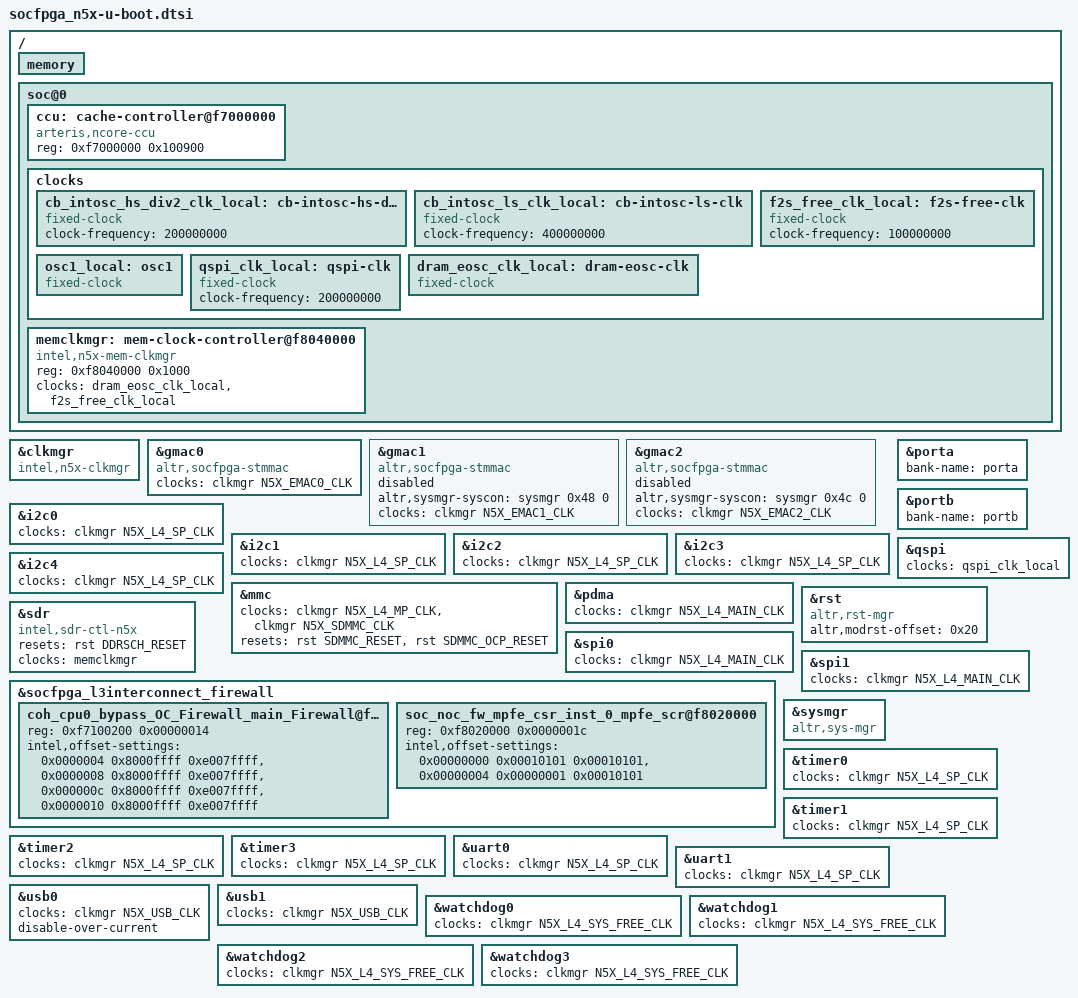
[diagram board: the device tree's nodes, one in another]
// SPDX-License-Identifier: GPL-2.0+
/*
 * U-Boot additions
 *
 * Copyright (C) 2020-2021 Intel Corporation <www.intel.com>
 */

#include "socfpga_soc64_u-boot.dtsi"
#include "socfpga_soc64_fit-u-boot.dtsi"
#include <dt-bindings/clock/n5x-clock.h>

/{
	memory {
		#address-cells = <2>;
		#size-cells = <2>;
		bootph-all;
	};

	soc@0 {
		bootph-all;

		ccu: cache-controller@f7000000 {
			compatible = "arteris,ncore-ccu";
			reg = <0xf7000000 0x100900>;
			bootph-all;
		};

		clocks {
			/* Local clock for U-Boot to see top-level clocks */
			cb_intosc_hs_div2_clk_local: cb-intosc-hs-div2-clk {
				#clock-cells = <0>;
				compatible = "fixed-clock";
				clock-frequency = <200000000>;
			};

			cb_intosc_ls_clk_local: cb-intosc-ls-clk {
				#clock-cells = <0>;
				compatible = "fixed-clock";
				clock-frequency = <400000000>;
			};

			f2s_free_clk_local: f2s-free-clk {
				#clock-cells = <0>;
				compatible = "fixed-clock";
				clock-frequency = <100000000>;
			};

			osc1_local: osc1 {
				#clock-cells = <0>;
				compatible = "fixed-clock";
			};

			qspi_clk_local: qspi-clk {
				#clock-cells = <0>;
				compatible = "fixed-clock";
				clock-frequency = <200000000>;
			};

			dram_eosc_clk_local: dram-eosc-clk {
				#clock-cells = <0>;
				compatible = "fixed-clock";
			};
		};

		memclkmgr: mem-clock-controller@f8040000 {
			compatible = "intel,n5x-mem-clkmgr";
			reg = <0xf8040000 0x1000>;
			#clock-cells = <0>;
			clocks = <&dram_eosc_clk_local>, <&f2s_free_clk_local>;
		};
	};
};

&clkmgr {
	compatible = "intel,n5x-clkmgr";
	bootph-all;
};

&gmac0 {
	compatible = "altr,socfpga-stmmac", "snps,dwmac-3.74a", "snps,dwmac";
	reset-names = "stmmaceth", "stmmaceth-ocp";
	clocks = <&clkmgr N5X_EMAC0_CLK>;
	clock-names = "stmmaceth";
	status = "okay";
};

&gmac1 {
	compatible = "altr,socfpga-stmmac", "snps,dwmac-3.74a", "snps,dwmac";
	reset-names = "stmmaceth", "stmmaceth-ocp";
	altr,sysmgr-syscon = <&sysmgr 0x48 0>;
	clocks = <&clkmgr N5X_EMAC1_CLK>;
	clock-names = "stmmaceth";
	status = "disabled";
};

&gmac2 {
	compatible = "altr,socfpga-stmmac", "snps,dwmac-3.74a", "snps,dwmac";
	reset-names = "stmmaceth", "stmmaceth-ocp";
	altr,sysmgr-syscon = <&sysmgr 0x4c 0>;
	clocks = <&clkmgr N5X_EMAC2_CLK>;
	clock-names = "stmmaceth";
	status = "disabled";
};

&i2c0 {
	clocks = <&clkmgr N5X_L4_SP_CLK>;
	reset-names = "i2c";
};

&i2c1 {
	clocks = <&clkmgr N5X_L4_SP_CLK>;
	reset-names = "i2c";
};

&i2c2 {
	clocks = <&clkmgr N5X_L4_SP_CLK>;
	reset-names = "i2c";
};

&i2c3 {
	clocks = <&clkmgr N5X_L4_SP_CLK>;
	reset-names = "i2c";
};

&i2c4 {
	clocks = <&clkmgr N5X_L4_SP_CLK>;
	reset-names = "i2c";
};

&memclkmgr {
	bootph-all;
};

&mmc {
	clocks = <&clkmgr N5X_L4_MP_CLK>,
		 <&clkmgr N5X_SDMMC_CLK>;
	resets = <&rst SDMMC_RESET>, <&rst SDMMC_OCP_RESET>;
};

&pdma {
	clocks = <&clkmgr N5X_L4_MAIN_CLK>;
};

&porta {
	bank-name = "porta";
};

&portb {
	bank-name = "portb";
};

&qspi {
	clocks = <&qspi_clk_local>;
	bootph-all;
};

&rst {
	compatible = "altr,rst-mgr";
	altr,modrst-offset = <0x20>;
	bootph-all;
};

&sdr {
	compatible = "intel,sdr-ctl-n5x";
	resets = <&rst DDRSCH_RESET>;
	clocks = <&memclkmgr>;
	clock-names = "mem_clk";
	bootph-all;
};

&spi0 {
	clocks = <&clkmgr N5X_L4_MAIN_CLK>;
};

&spi1 {
	clocks = <&clkmgr N5X_L4_MAIN_CLK>;
};

&socfpga_l3interconnect_firewall {
	coh_cpu0_bypass_OC_Firewall_main_Firewall@f7100200 {
		reg = <0xf7100200 0x00000014>;
		intel,offset-settings =
			/* Disable ocram security at CCU for non secure access */
			<0x0000004 0x8000ffff 0xe007ffff>,
			<0x0000008 0x8000ffff 0xe007ffff>,
			<0x000000c 0x8000ffff 0xe007ffff>,
			<0x0000010 0x8000ffff 0xe007ffff>;
		bootph-all;
	};

	soc_noc_fw_mpfe_csr_inst_0_mpfe_scr@f8020000 {
		reg = <0xf8020000 0x0000001c>;
		intel,offset-settings =
			/* Disable MPFE firewall for SMMU */
			<0x00000000 0x00010101 0x00010101>,
			/* Disable MPFE firewall for HMC adapter */
			<0x00000004 0x00000001 0x00010101>;
		bootph-all;
	};
};

&sysmgr {
	compatible = "altr,sys-mgr", "syscon";
	bootph-all;
};

&timer0 {
	clocks = <&clkmgr N5X_L4_SP_CLK>;
};

&timer1 {
	clocks = <&clkmgr N5X_L4_SP_CLK>;
};

&timer2 {
	clocks = <&clkmgr N5X_L4_SP_CLK>;
};

&timer3 {
	clocks = <&clkmgr N5X_L4_SP_CLK>;
};

&uart0 {
	clocks = <&clkmgr N5X_L4_SP_CLK>;
	bootph-all;
};

&uart1 {
	clocks = <&clkmgr N5X_L4_SP_CLK>;
};

&usb0 {
	clocks = <&clkmgr N5X_USB_CLK>;
	disable-over-current;
	bootph-all;
};

&usb1 {
	clocks = <&clkmgr N5X_USB_CLK>;
	bootph-all;
};

&watchdog0 {
	clocks = <&clkmgr N5X_L4_SYS_FREE_CLK>;
	bootph-all;
};

&watchdog1 {
	clocks = <&clkmgr N5X_L4_SYS_FREE_CLK>;
};

&watchdog2 {
	clocks = <&clkmgr N5X_L4_SYS_FREE_CLK>;
};

&watchdog3 {
	clocks = <&clkmgr N5X_L4_SYS_FREE_CLK>;
};
